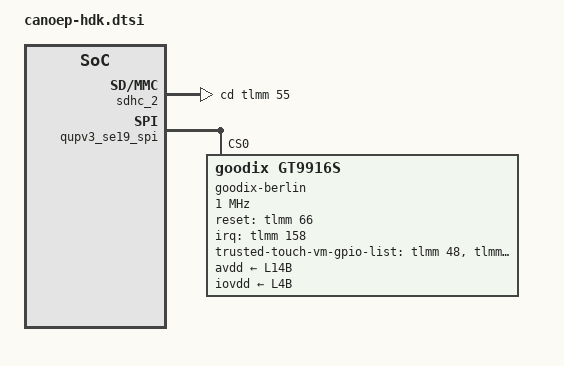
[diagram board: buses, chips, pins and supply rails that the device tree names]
// SPDX-License-Identifier: BSD-3-Clause
/*
 * Copyright (c) Qualcomm Technologies, Inc. and/or its subsidiaries.
 */

#include "canoe-qrd-st54l-pandeiro.dtsi"

&sdhc_2 {
	cd-gpios = <&tlmm 55 GPIO_ACTIVE_HIGH>;
};

&qupv3_se19_spi {
	#address-cells = <1>;
	#size-cells = <0>;
	status = "ok";
	qcom,touch-active = "goodix,gt9916S";
	qcom,la-vm;

	st_fts@0 {
		status = "disabled";
	};

	goodix-berlin@0 {
		compatible = "goodix,gt9916S";
		reg = <0>;
		spi-max-frequency = <1000000>;

		goodix,avdd-name = "avdd";
		avdd-supply = <&L14B>;
		goodix,iovdd-name = "iovdd";
		iovdd-supply = <&L4B>;

		interrupt-parent = <&tlmm>;
		interrupts = <158 0x2008>;
		goodix,reset-gpio = <&tlmm 66 0x00>;
		goodix,irq-gpio = <&tlmm 158 0x2008>;
		goodix,irq-flags = <2>;
		goodix,panel-max-x = <1080>;
		goodix,panel-max-y = <2400>;
		goodix,panel-max-w = <255>;
		goodix,panel-max-p = <4096>;
		goodix,firmware-name = "goodix_firmware_spi.bin";
		goodix,config-name = "goodix_cfg_group_spi.bin";

		pinctrl-names = "pmx_ts_active", "pmx_ts_suspend", "pmx_ts_release";
		pinctrl-0 = <&ts_active>;
		pinctrl-1 = <&ts_int_suspend &ts_reset_suspend>;
		pinctrl-2 = <&ts_release>;

		goodix,touch-type = "primary";
		goodix,qts_en;
		qts,trusted-touch-mode = "vm_mode";
		qts,touch-environment = "pvm";
		qts,trusted-touch-type = "primary";
		qts,trusted-touch-spi-irq = <647>;
		qts,trusted-touch-io-bases = <0x1a80000>;
		qts,trusted-touch-io-sizes = <0x1000>;
		qts,trusted-touch-vm-gpio-list = <&tlmm 48 0 &tlmm 49 0 &tlmm 50 0
						&tlmm 51 0 &tlmm 66 0 &tlmm 158 0x2008>;
	};
};
